AUTOSAR XML (schema 00045)
package /HlaAdapter
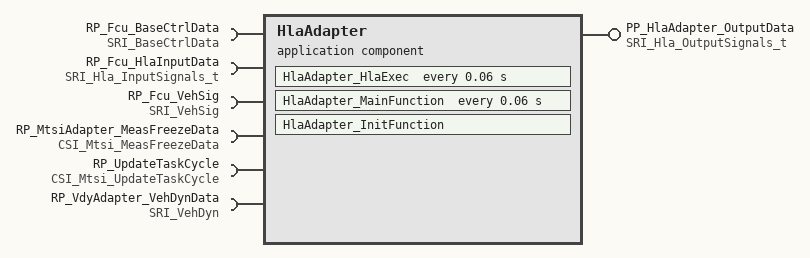
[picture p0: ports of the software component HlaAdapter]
  application sw component type HlaAdapter
    provide port PP_HlaAdapter_OutputData: provided-interface=SRI_Hla_OutputSignals_t
    6 x require port:
      RP_Fcu_BaseCtrlData: required-interface=SRI_BaseCtrlData
      RP_Fcu_HlaInputData: required-interface=SRI_Hla_InputSignals_t
      RP_Fcu_VehSig: required-interface=SRI_VehSig
      RP_MtsiAdapter_MeasFreezeData: required-interface=CSI_Mtsi_MeasFreezeData
      RP_UpdateTaskCycle: required-interface=CSI_Mtsi_UpdateTaskCycle
      RP_VdyAdapter_VehDynData: required-interface=SRI_VehDyn
    behavior HlaAdapter_IB: handle-termination-and-restart=NO-SUPPORT
      init event InitEvent_HlaAdapter_InitFunction: start-on-event=HlaAdapter_InitFunction
      timing event TimingEvent_HlaAdapter_HlaExec: start-on-event=HlaAdapter_HlaExec, period=0.06
      timing event TimingEvent_HlaAdapter_MainFunction: start-on-event=HlaAdapter_MainFunction, period=0.06
      runnable HlaAdapter_HlaExec
        data-receive-point-by-arguments:
          access drparg_BaseCtrlData: accessed-variable=RP_Fcu_BaseCtrlData.BaseCtrlData
          access drparg_VehSig: accessed-variable=RP_Fcu_VehSig.VehSig
      runnable HlaAdapter_InitFunction
        data-receive-point-by-arguments:
          access drparg_BaseCtrlData: accessed-variable=RP_Fcu_BaseCtrlData.BaseCtrlData
          access drparg_VehSig: accessed-variable=RP_Fcu_VehSig.VehSig
      runnable HlaAdapter_MainFunction
        data-receive-point-by-arguments:
          4 x access:
            drparg_BaseCtrlData: accessed-variable=RP_Fcu_BaseCtrlData.BaseCtrlData
            drparg_VehDyn: accessed-variable=RP_VdyAdapter_VehDynData.VehDyn
            drparg_Hla_InputSignals_t: accessed-variable=RP_Fcu_HlaInputData.Hla_InputSignals_t
            drparg_VehSig: accessed-variable=RP_Fcu_VehSig.VehSig
        data-send-points:
          access dsp_Hla_OutputSignals_t: accessed-variable=PP_HlaAdapter_OutputData.Hla_OutputSignals_t
        sync call scp_MeasFreezeData: operation=RP_MtsiAdapter_MeasFreezeData.MeasFreezeData, timeout=0.0
        sync call scp_UpdateTaskCycle: operation=RP_UpdateTaskCycle.UpdateTaskCycle, timeout=0.0
  swc implementation HlaAdapterImpl: programming-language=C, sw-version=1.0.0, vendor-id=0, behavior=HlaAdapter_IB
    code-descriptors:
      code CodeGen: artifact-descriptors=[{short-label=SWHDR, category=SWHDR}, {short-label=SWSRC, category=SWSRC}]
    resource consumption Resource
      memory section CODE: sw-addrmethod=CODE
      memory section VAR_UNSPECIFIED: sw-addrmethod=VAR
